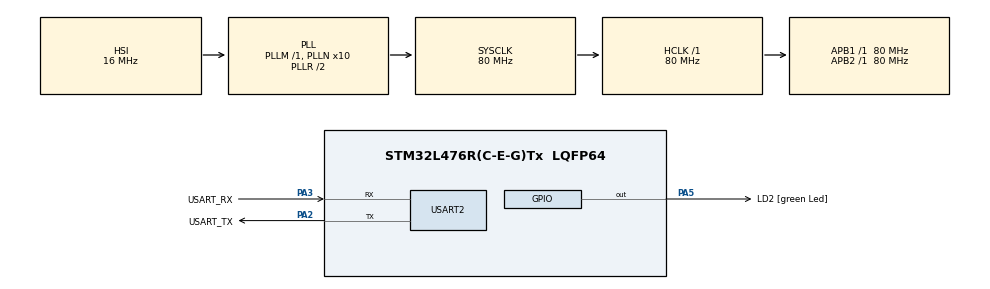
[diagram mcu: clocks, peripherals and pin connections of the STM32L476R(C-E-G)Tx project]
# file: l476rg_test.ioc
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Dma.Request0=USART2_RX
Dma.Request1=USART2_TX
Dma.USART2_RX.0.Direction=DMA_PERIPH_TO_MEMORY
Dma.USART2_RX.0.Instance=DMA1_Channel6
Dma.USART2_RX.0.MemDataAlignment=DMA_MDATAALIGN_BYTE
Dma.USART2_RX.0.MemInc=DMA_MINC_ENABLE
Dma.USART2_RX.0.Mode=DMA_CIRCULAR
Dma.USART2_RX.0.PeriphDataAlignment=DMA_PDATAALIGN_BYTE
Dma.USART2_RX.0.PeriphInc=DMA_PINC_DISABLE
Dma.USART2_RX.0.Priority=DMA_PRIORITY_VERY_HIGH
Dma.USART2_TX.1.Direction=DMA_MEMORY_TO_PERIPH
Dma.USART2_TX.1.Instance=DMA1_Channel7
Dma.USART2_TX.1.MemDataAlignment=DMA_MDATAALIGN_BYTE
Dma.USART2_TX.1.MemInc=DMA_MINC_ENABLE
Dma.USART2_TX.1.Mode=DMA_NORMAL
Dma.USART2_TX.1.PeriphDataAlignment=DMA_PDATAALIGN_BYTE
Dma.USART2_TX.1.PeriphInc=DMA_PINC_DISABLE
Dma.USART2_TX.1.Priority=DMA_PRIORITY_VERY_HIGH
FREERTOS.Tasks01=defaultTask,24,3000,StartDefaultTask,Default,NULL,Dynamic,NULL,NULL
FREERTOS.configTOTAL_HEAP_SIZE=20000
Mcu.Family=STM32L4
Mcu.Name=STM32L476R(C-E-G)Tx
Mcu.Package=LQFP64
NVIC.DMA1_Channel6_IRQn=true\:5\:0\:false\:false\:true\:true\:false\:true
NVIC.DMA1_Channel7_IRQn=true\:5\:0\:false\:false\:true\:true\:false\:true
NVIC.PriorityGroup=NVIC_PRIORITYGROUP_4
NVIC.USART2_IRQn=true\:5\:0\:false\:false\:true\:true\:true\:true
PA2.GPIO_Label=USART_TX
PA2.GPIO_Mode=GPIO_MODE_AF_PP
PA2.GPIO_PuPd=GPIO_NOPULL
PA2.GPIO_Speed=GPIO_SPEED_FREQ_VERY_HIGH
PA2.Mode=Asynchronous
PA2.Signal=USART2_TX
PA3.GPIO_Label=USART_RX
PA3.GPIO_Mode=GPIO_MODE_AF_PP
PA3.GPIO_PuPd=GPIO_NOPULL
PA3.GPIO_Speed=GPIO_SPEED_FREQ_VERY_HIGH
PA3.Mode=Asynchronous
PA3.Signal=USART2_RX
PA5.GPIO_Label=LD2 [green Led]
PA5.GPIO_ModeDefaultOutputPP=GPIO_MODE_OUTPUT_PP
PA5.GPIO_PuPd=GPIO_NOPULL
PA5.GPIO_Speed=GPIO_SPEED_FREQ_LOW
PA5.Signal=GPIO_Output
ProjectManager.HeapSize=0x200
ProjectManager.StackSize=0x400
ProjectManager.TargetToolchain=SW4STM32
RCC.ADCFreq_Value=64000000
RCC.AHBFreq_Value=80000000
RCC.APB1Freq_Value=80000000
RCC.APB1TimFreq_Value=80000000
RCC.APB2Freq_Value=80000000
RCC.APB2TimFreq_Value=80000000
RCC.CortexFreq_Value=80000000
RCC.HCLKFreq_Value=80000000
RCC.HSE_VALUE=8000000
RCC.HSI_VALUE=16000000
RCC.LSE_VALUE=32768
RCC.MSIClockRange=RCC_MSIRANGE_11
RCC.MSI_VALUE=48000000
RCC.PLLN=10
RCC.PLLSourceVirtual=RCC_PLLSOURCE_HSI
RCC.PREFETCH_ENABLE=1
RCC.SYSCLKFreq_VALUE=80000000
RCC.SYSCLKSource=RCC_SYSCLKSOURCE_PLLCLK
RCC.USBFreq_Value=64000000
RCC.VCOOutputFreq_Value=160000000
USART2.VirtualMode-Asynchronous=VM_ASYNC
VP_FREERTOS_VS_CMSIS_V2.Mode=CMSIS_V2
board=NUCLEO-L476RG

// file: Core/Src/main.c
/* USER CODE BEGIN Header */
/**
 ******************************************************************************
 * @file           : main.c
 * @brief          : Main program body
 ******************************************************************************
 * @attention
 *
 * <h2><center>&copy; Copyright (c) 2021 STMicroelectronics.
 * All rights reserved.</center></h2>
 *
 * This software component is licensed by ST under Ultimate Liberty license
 * SLA0044, the "License"; You may not use this file except in compliance with
 * the License. You may obtain a copy of the License at:
 *                             www.st.com/SLA0044
 *
 ******************************************************************************
 */
/* USER CODE END Header */
#include "main.h"
#include "cmsis_os.h"

/* USER CODE BEGIN Includes */
#include <rcl/error_handling.h>
#include <rcl/rcl.h>
#include <rclc/rclc.h>
#include <rcutils/stdatomic_helper/gcc/stdatomic.h>
#include <rmw_microros/rmw_microros.h>
#include <uxr/client/transport.h>

#include <std_msgs/msg/float32.h>
#include <std_msgs/msg/int32.h>
/* USER CODE END Includes */

UART_HandleTypeDef huart2;
DMA_HandleTypeDef hdma_usart2_rx;
DMA_HandleTypeDef hdma_usart2_tx;

/* Definitions for defaultTask */
osThreadId_t defaultTaskHandle;
const osThreadAttr_t defaultTask_attributes = {
    .name = "defaultTask",
    .stack_size = 3000 * 4,
    .priority = (osPriority_t)osPriorityNormal,
};
/* USER CODE BEGIN PV */
// void __sync_synchronize() {}
/* USER CODE END PV */

void SystemClock_Config(void);
static void MX_GPIO_Init(void);
static void MX_DMA_Init(void);
static void MX_USART2_UART_Init(void);
void StartDefaultTask(void *argument);

int main(void) {

  /* MCU Configuration--------------------------------------------------------*/

  /* Reset of all peripherals, Initializes the Flash interface and the Systick.
   */
  HAL_Init();

  /* Configure the system clock */
  SystemClock_Config();

  /* Initialize all configured peripherals */
  MX_GPIO_Init();
  MX_DMA_Init();
  MX_USART2_UART_Init();

  /* Init scheduler */
  osKernelInitialize();

  /* Create the thread(s) */
  /* creation of defaultTask */
  defaultTaskHandle =
      osThreadNew(StartDefaultTask, NULL, &defaultTask_attributes);

  /* Start scheduler */
  osKernelStart();

  /* We should never get here as control is now taken by the scheduler */
  /* Infinite loop */
  while (1) {

  }
}

void SystemClock_Config(void) {
  RCC_OscInitTypeDef RCC_OscInitStruct = {0};
  RCC_ClkInitTypeDef RCC_ClkInitStruct = {0};
  RCC_PeriphCLKInitTypeDef PeriphClkInit = {0};

  /** Initializes the RCC Oscillators according to the specified parameters
   * in the RCC_OscInitTypeDef structure.
   */
  RCC_OscInitStruct.OscillatorType = RCC_OSCILLATORTYPE_HSI;
  RCC_OscInitStruct.HSIState = RCC_HSI_ON;
  RCC_OscInitStruct.HSICalibrationValue = RCC_HSICALIBRATION_DEFAULT;
  RCC_OscInitStruct.PLL.PLLState = RCC_PLL_ON;
  RCC_OscInitStruct.PLL.PLLSource = RCC_PLLSOURCE_HSI;
  RCC_OscInitStruct.PLL.PLLM = 1;
  RCC_OscInitStruct.PLL.PLLN = 10;
  RCC_OscInitStruct.PLL.PLLP = RCC_PLLP_DIV7;
  RCC_OscInitStruct.PLL.PLLQ = RCC_PLLQ_DIV2;
  RCC_OscInitStruct.PLL.PLLR = RCC_PLLR_DIV2;
  if (HAL_RCC_OscConfig(&RCC_OscInitStruct) != HAL_OK) {
    Error_Handler();
  }
  /** Initializes the CPU, AHB and APB buses clocks
   */
  RCC_ClkInitStruct.ClockType = RCC_CLOCKTYPE_HCLK | RCC_CLOCKTYPE_SYSCLK |
                                RCC_CLOCKTYPE_PCLK1 | RCC_CLOCKTYPE_PCLK2;
  RCC_ClkInitStruct.SYSCLKSource = RCC_SYSCLKSOURCE_PLLCLK;
  RCC_ClkInitStruct.AHBCLKDivider = RCC_SYSCLK_DIV1;
  RCC_ClkInitStruct.APB1CLKDivider = RCC_HCLK_DIV1;
  RCC_ClkInitStruct.APB2CLKDivider = RCC_HCLK_DIV1;

  if (HAL_RCC_ClockConfig(&RCC_ClkInitStruct, FLASH_LATENCY_4) != HAL_OK) {
    Error_Handler();
  }
  PeriphClkInit.PeriphClockSelection = RCC_PERIPHCLK_USART2;
  PeriphClkInit.Usart2ClockSelection = RCC_USART2CLKSOURCE_PCLK1;
  if (HAL_RCCEx_PeriphCLKConfig(&PeriphClkInit) != HAL_OK) {
    Error_Handler();
  }
  /** Configure the main internal regulator output voltage
   */
  if (HAL_PWREx_ControlVoltageScaling(PWR_REGULATOR_VOLTAGE_SCALE1) != HAL_OK) {
    Error_Handler();
  }
}

static void MX_USART2_UART_Init(void) {

  huart2.Instance = USART2;
  huart2.Init.BaudRate = 115200;
  huart2.Init.WordLength = UART_WORDLENGTH_8B;
  huart2.Init.StopBits = UART_STOPBITS_1;
  huart2.Init.Parity = UART_PARITY_NONE;
  huart2.Init.Mode = UART_MODE_TX_RX;
  huart2.Init.HwFlowCtl = UART_HWCONTROL_NONE;
  huart2.Init.OverSampling = UART_OVERSAMPLING_16;
  huart2.Init.OneBitSampling = UART_ONE_BIT_SAMPLE_DISABLE;
  huart2.AdvancedInit.AdvFeatureInit = UART_ADVFEATURE_NO_INIT;
  if (HAL_UART_Init(&huart2) != HAL_OK) {
    Error_Handler();
  }
}

static void MX_DMA_Init(void) {

  /* DMA controller clock enable */
  __HAL_RCC_DMA1_CLK_ENABLE();

  /* DMA interrupt init */
  /* DMA1_Channel6_IRQn interrupt configuration */
  HAL_NVIC_SetPriority(DMA1_Channel6_IRQn, 5, 0);
  HAL_NVIC_EnableIRQ(DMA1_Channel6_IRQn);
  /* DMA1_Channel7_IRQn interrupt configuration */
  HAL_NVIC_SetPriority(DMA1_Channel7_IRQn, 5, 0);
  HAL_NVIC_EnableIRQ(DMA1_Channel7_IRQn);
}

static void MX_GPIO_Init(void) {
  GPIO_InitTypeDef GPIO_InitStruct = {0};

  /* GPIO Ports Clock Enable */
  __HAL_RCC_GPIOA_CLK_ENABLE();

  /*Configure GPIO pin Output Level */
  HAL_GPIO_WritePin(LD2_GPIO_Port, LD2_Pin, GPIO_PIN_RESET);

  /*Configure GPIO pin : LD2_Pin */
  GPIO_InitStruct.Pin = LD2_Pin;
  GPIO_InitStruct.Mode = GPIO_MODE_OUTPUT_PP;
  GPIO_InitStruct.Pull = GPIO_NOPULL;
  GPIO_InitStruct.Speed = GPIO_SPEED_FREQ_LOW;
  HAL_GPIO_Init(LD2_GPIO_Port, &GPIO_InitStruct);
}

/* USER CODE BEGIN 4 */
bool cubemx_transport_open(struct uxrCustomTransport *transport);
bool cubemx_transport_close(struct uxrCustomTransport *transport);
size_t cubemx_transport_write(struct uxrCustomTransport *transport,
                              const uint8_t *buf, size_t len, uint8_t *err);
size_t cubemx_transport_read(struct uxrCustomTransport *transport, uint8_t *buf,
                             size_t len, int timeout, uint8_t *err);

void *microros_allocate(size_t size, void *state);
void microros_deallocate(void *pointer, void *state);
void *microros_reallocate(void *pointer, size_t size, void *state);
void *microros_zero_allocate(size_t number_of_elements, size_t size_of_element,
                             void *state);
/* USER CODE END 4 */

void StartDefaultTask(void *argument) {
  /* USER CODE BEGIN 5 */
  rmw_uros_set_custom_transport(true, (void *)&huart2, cubemx_transport_open,
                                cubemx_transport_close, cubemx_transport_write,
                                cubemx_transport_read);

  rcl_allocator_t freeRTOS_allocator = rcutils_get_zero_initialized_allocator();
  freeRTOS_allocator.allocate = microros_allocate;
  freeRTOS_allocator.deallocate = microros_deallocate;
  freeRTOS_allocator.reallocate = microros_reallocate;
  freeRTOS_allocator.zero_allocate = microros_zero_allocate;

  if (!rcutils_set_default_allocator(&freeRTOS_allocator)) {
    printf("Error on default allocators (line %d)\n", __LINE__);
  }

  // micro-ROS app

  rcl_publisher_t publisher, second_publisher;
  std_msgs__msg__Int32 msg;
  std_msgs__msg__Float32 msg_f;
  rclc_support_t support;
  rcl_allocator_t allocator;
  rcl_node_t node;

  allocator = rcl_get_default_allocator();

  // create init_options
  rclc_support_init(&support, 0, NULL, &allocator);

  // create node
  rclc_node_init_default(&node, "cubemx_node", "", &support);

  // create publisher
  rclc_publisher_init_default(&publisher, &node,
                              ROSIDL_GET_MSG_TYPE_SUPPORT(std_msgs, msg, Int32),
                              "cubemx_publisher");

  rclc_publisher_init_default(
      &second_publisher, &node,
      ROSIDL_GET_MSG_TYPE_SUPPORT(std_msgs, msg, Float32), "second_publisher");

  msg.data = 0;
  msg_f.data = 1.23f;

  for (;;) {
    rcl_ret_t ret = rcl_publish(&publisher, &msg, NULL);
    // rcl_publish(&second_publisher, &msg_f, NULL);
    if (ret != RCL_RET_OK) {
      printf("Error publishing (line %d)\n", __LINE__);
      NVIC_SystemReset();
    }

    msg.data++;
    osDelay(10);
  }

  /* USER CODE END 5 */
}

void Error_Handler(void) {
  __disable_irq();
  while (1) {
  }
}

#ifdef USE_FULL_ASSERT
/**
 * @brief  Reports the name of the source file and the source line number
 *         where the assert_param error has occurred.
 * @param  file: pointer to the source file name
 * @param  line: assert_param error line source number
 * @retval None
 */
void assert_failed(uint8_t *file, uint32_t line) {
  /* USER CODE BEGIN 6 */
  /* User can add his own implementation to report the file name and line
     number,
     ex: printf("Wrong parameters value: file %s on line %d\r\n", file, line) */
  /* USER CODE END 6 */
}
#endif /* USE_FULL_ASSERT */

/************************ (C) COPYRIGHT STMicroelectronics *****END OF FILE****/

#pragma clang diagnostic pop
